AUTOSAR XML (schema 4-0-3)
standard types defined: Boolean, UInt16, UInt32, UInt8
package /AUTOSAR_Platform/DataConstrs
  range DC_Boolean: raw 0..1
  range DC_UInt16: raw 0..65535
  range DC_UInt8: raw 0..255
package /PATAC/MSM/ComponentTypes
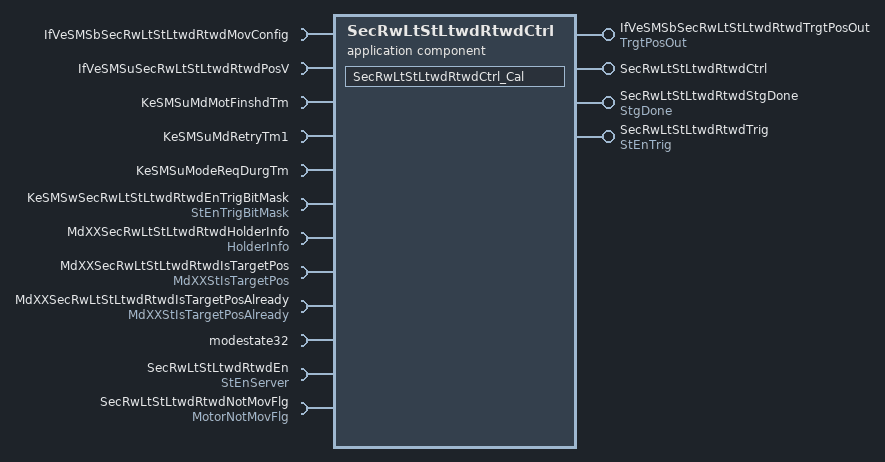
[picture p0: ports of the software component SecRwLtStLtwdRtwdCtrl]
  application sw component type SecRwLtStLtwdRtwdCtrl
    4 x provide port:
      IfVeSMSbSecRwLtStLtwdRtwdTrgtPosOut: nonqueued-sender-com-spec{data-element=TrgtPosOut/Val, init-value=0}, provided-interface=TrgtPosOut
      SecRwLtStLtwdRtwdCtrl: server-com-spec{operation=Cal, queue-length=1}, provided-interface=SecRwLtStLtwdRtwdCtrl
      SecRwLtStLtwdRtwdStgDone: nonqueued-sender-com-spec{data-element=StgDone/Val, init-value=0}, provided-interface=StgDone
      SecRwLtStLtwdRtwdTrig: nonqueued-sender-com-spec{data-element=StEnTrig/Val, init-value=0}, provided-interface=StEnTrig
    12 x require port:
      IfVeSMSbSecRwLtStLtwdRtwdMovConfig: nonqueued-receiver-com-spec{data-element=IfVeSMSbSecRwLtStLtwdRtwdMovConfig/Val, filter=data-filter-type=ALWAYS, init-value=0}, required-interface=IfVeSMSbSecRwLtStLtwdRtwdMovConfig
      IfVeSMSuSecRwLtStLtwdRtwdPosV: nonqueued-receiver-com-spec{data-element=IfVeSMSuSecRwLtStLtwdRtwdPosV/Val, filter=data-filter-type=ALWAYS, init-value=0}, required-interface=IfVeSMSuSecRwLtStLtwdRtwdPosV
      KeSMSuMdMotFinshdTm: parameter-require-com-spec{init-value=0, parameter=KeSMSuMdMotFinshdTm/Val}, required-interface=KeSMSuMdMotFinshdTm
      KeSMSuMdRetryTm1: parameter-require-com-spec{init-value=0, parameter=KeSMSuMdRetryTm1/Val}, required-interface=KeSMSuMdRetryTm1
      KeSMSuModeReqDurgTm: parameter-require-com-spec{init-value=0, parameter=KeSMSuModeReqDurgTm/Val}, required-interface=KeSMSuModeReqDurgTm
      KeSMSwSecRwLtStLtwdRtwdEnTrigBitMask: parameter-require-com-spec{init-value=6153, parameter=StEnTrigBitMask/Val}, required-interface=StEnTrigBitMask
      MdXXSecRwLtStLtwdRtwdHolderInfo: nonqueued-receiver-com-spec{data-element=HolderInfo/Val, filter=data-filter-type=ALWAYS, init-value=0}, required-interface=HolderInfo
      MdXXSecRwLtStLtwdRtwdIsTargetPos: nonqueued-receiver-com-spec{data-element=MdXXStIsTargetPos/Val, filter=data-filter-type=ALWAYS, init-value=0}, required-interface=MdXXStIsTargetPos
      MdXXSecRwLtStLtwdRtwdIsTargetPosAlready: nonqueued-receiver-com-spec{data-element=MdXXStIsTargetPosAlready/Val, filter=data-filter-type=ALWAYS, init-value=0}, required-interface=MdXXStIsTargetPosAlready
      modestate32: nonqueued-receiver-com-spec{data-element=modestate32/Val, filter=data-filter-type=ALWAYS, init-value=0}, required-interface=modestate32
      SecRwLtStLtwdRtwdEn: required-com-specs=[Clear, Get, Set], required-interface=StEnServer
      SecRwLtStLtwdRtwdNotMovFlg: nonqueued-receiver-com-spec{data-element=MotorNotMovFlg/Val, filter=data-filter-type=ALWAYS, init-value=0}, required-interface=MotorNotMovFlg
    behavior SecRwLtStLtwdRtwdCtrl_InternalBehavior
      operation invoked event OIT_SecRwLtStLtwdRtwdCtrl_Cal_SecRwLtStLtwdRtwdCtrl_Cal: start-on-event=SecRwLtStLtwdRtwdCtrl_Cal, operation=SecRwLtStLtwdRtwdCtrl.Cal
      runnable SecRwLtStLtwdRtwdCtrl_Cal
        data-receive-point-by-arguments:
          7 x access:
            REC_IfVeSMSbSecRwLtStLtwdRtwdMovConfig_Val: accessed-variable=IfVeSMSbSecRwLtStLtwdRtwdMovConfig.Val
            REC_IfVeSMSuSecRwLtStLtwdRtwdPosV_Val: accessed-variable=IfVeSMSuSecRwLtStLtwdRtwdPosV.Val
            REC_MdXXSecRwLtStLtwdRtwdHolderInfo_Val: accessed-variable=MdXXSecRwLtStLtwdRtwdHolderInfo.Val
            REC_MdXXSecRwLtStLtwdRtwdIsTargetPos_Val: accessed-variable=MdXXSecRwLtStLtwdRtwdIsTargetPos.Val
            REC_MdXXSecRwLtStLtwdRtwdIsTargetPosAlready_Val: accessed-variable=MdXXSecRwLtStLtwdRtwdIsTargetPosAlready.Val
            REC_modestate32_Val: accessed-variable=modestate32.Val
            REC_SecRwLtStLtwdRtwdNotMovFlg_Val: accessed-variable=SecRwLtStLtwdRtwdNotMovFlg.Val
        data-send-points:
          access SEND_IfVeSMSbSecRwLtStLtwdRtwdTrgtPosOut_Val: accessed-variable=IfVeSMSbSecRwLtStLtwdRtwdTrgtPosOut.Val
          access SEND_SecRwLtStLtwdRtwdStgDone_Val: accessed-variable=SecRwLtStLtwdRtwdStgDone.Val
          access SEND_SecRwLtStLtwdRtwdTrig_Val: accessed-variable=SecRwLtStLtwdRtwdTrig.Val
        4 x parameter access:
          PA_KeSMSuMdMotFinshdTm_Val: accessed-parameter=KeSMSuMdMotFinshdTm.Val
          PA_KeSMSuMdRetryTm1_Val: accessed-parameter=KeSMSuMdRetryTm1.Val
          PA_KeSMSuModeReqDurgTm_Val: accessed-parameter=KeSMSuModeReqDurgTm.Val
          PA_KeSMSwSecRwLtStLtwdRtwdEnTrigBitMask_Val: accessed-parameter=KeSMSwSecRwLtStLtwdRtwdEnTrigBitMask.Val
        sync call SC_SecRwLtStLtwdRtwdEn_Get: operation=SecRwLtStLtwdRtwdEn.Get, timeout=0
  swc implementation SecRwLtStLtwdRtwdCtrl_Implementation: behavior=SecRwLtStLtwdRtwdCtrl_InternalBehavior
    code-descriptors:
      code Default: artifact-descriptors=autosar-engineering-object={short-label=Default, category=SWSRC}
package /PATAC/MSM/ModeAdjust/CalPortInterface
  parameter interface KeSMSuMdMotFinshdTm
    parameter data prototype Val: sw-calibration-access=READ-WRITE, type=UInt16
  parameter interface KeSMSuModeReqDurgTm
    parameter data prototype Val: sw-calibration-access=READ-WRITE, type=UInt16
  parameter interface StEnTrigBitMask
    parameter data prototype Val: sw-calibration-access=READ-WRITE, type=UInt32
package /PATAC/MSM/ModeAdjust/Interfaces
  sender receiver interface IfVeSMSuSecRwLtStLtwdRtwdPosV: invalidation-policy{data-element=IfVeSMSuSecRwLtStLtwdRtwdPosV/Val, handle-invalid=DONT-INVALIDATE}
    data Val: type=Boolean
package /PATAC/MSM/ModeAdjust/PortInterface
  client server interface SecRwLtStLtwdRtwdCtrl
    operation Cal
  client server interface StEnServer
    operation Clear
      arg data: type=UInt8, direction=IN, server-argument-impl-policy=USE-ARGUMENT-TYPE
    operation Get
      arg data: type=UInt32, direction=OUT, server-argument-impl-policy=USE-ARGUMENT-TYPE
    operation Set
      arg data: type=UInt8, direction=IN, server-argument-impl-policy=USE-ARGUMENT-TYPE
  8 x sender receiver interface:
    HolderInfo: invalidation-policy{data-element=HolderInfo/Val, handle-invalid=DONT-INVALIDATE}
      data Val: type=UInt32
    MdXXStIsTargetPos: invalidation-policy{data-element=MdXXStIsTargetPos/Val, handle-invalid=DONT-INVALIDATE}
      data Val: type=UInt32
    MdXXStIsTargetPosAlready: invalidation-policy{data-element=MdXXStIsTargetPosAlready/Val, handle-invalid=DONT-INVALIDATE}
      data Val: type=UInt32
    modestate32: invalidation-policy{data-element=modestate32/Val, handle-invalid=DONT-INVALIDATE}
      data Val: type=UInt32
    MotorNotMovFlg: invalidation-policy{data-element=MotorNotMovFlg/Val, handle-invalid=DONT-INVALIDATE}
      data Val: type=Boolean
    StEnTrig: invalidation-policy{data-element=StEnTrig/Val, handle-invalid=DONT-INVALIDATE}
      data Val: type=Boolean
    StgDone: invalidation-policy{data-element=StgDone/Val, handle-invalid=DONT-INVALIDATE}
      data Val: type=Boolean
    TrgtPosOut: invalidation-policy{data-element=TrgtPosOut/Val, handle-invalid=DONT-INVALIDATE}
      data Val: type=Boolean
package /PATAC/MSM/PortInterfaces
  parameter interface KeSMSuMdRetryTm1
    parameter data prototype Val: sw-calibration-access=READ-WRITE, type=UInt8
  sender receiver interface IfVeSMSbSecRwLtStLtwdRtwdMovConfig: invalidation-policy{data-element=IfVeSMSbSecRwLtStLtwdRtwdMovConfig/Val, handle-invalid=DONT-INVALIDATE}
    data Val: type=Boolean
